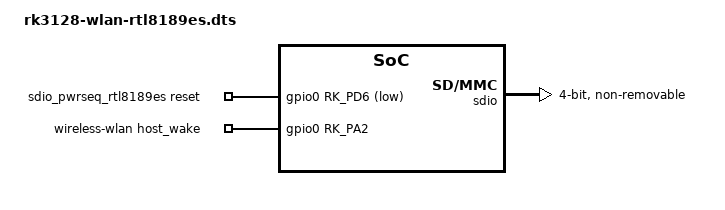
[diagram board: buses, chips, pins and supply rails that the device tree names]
// SPDX-License-Identifier: (GPL-2.0+ OR MIT)
/*
 * RK3128 WLAN overlay for boards populated with RTL8189ES.
 */

/dts-v1/;
/plugin/;

#include <dt-bindings/gpio/gpio.h>
#include <dt-bindings/pinctrl/rockchip.h>

/ {
	fragment@0 {
		target-path = "/";
		__overlay__ {
			sdio_pwrseq_rtl8189es: sdio-pwrseq-rtl8189es {
				compatible = "mmc-pwrseq-simple";
				clocks = <&xin32k>;
				clock-names = "ext_clock";
				pinctrl-names = "default";
				pinctrl-0 = <&wifi_enable_h_rtl8189es>;
				reset-gpios = <&gpio0 RK_PD6 GPIO_ACTIVE_LOW>;
				status = "okay";
			};

			wireless-wlan {
				compatible = "wlan-platdata";
				rockchip,grf = <&grf>;
				clocks = <&xin32k>;
				clock-names = "clk_wifi";
				ref-clock-frequency = <32768>;
				wifi_chip_type = "rtl8189es";
				WIFI,host_wake-gpios = <&gpio0 RK_PA2 GPIO_ACTIVE_HIGH>;
				status = "okay";
			};
		};
	};

	fragment@1 {
		target = <&pinctrl>;
		__overlay__ {
			sdio-pwrseq {
				wifi_enable_h_rtl8189es: wifi-enable-h-rtl8189es {
					rockchip,pins = <0 RK_PD6 RK_FUNC_GPIO &pcfg_pull_none>;
				};
			};
		};
	};

	fragment@2 {
		target = <&sdio>;
		__overlay__ {
			mmc-pwrseq = <&sdio_pwrseq_rtl8189es>;
			rockchip,no-dmaengine;
			max-frequency = <37500000>;
			bus-width = <4>;
			cap-sd-highspeed;
			cap-sdio-irq;
			supports-sdio;
			disable-wp;
			ignore-pm-notify;
			keep-power-in-suspend;
			pinctrl-names = "default";
			pinctrl-0 = <&sdio_cmd &sdio_clk &sdio_bus4>;
			non-removable;
			status = "okay";
		};
	};
};
